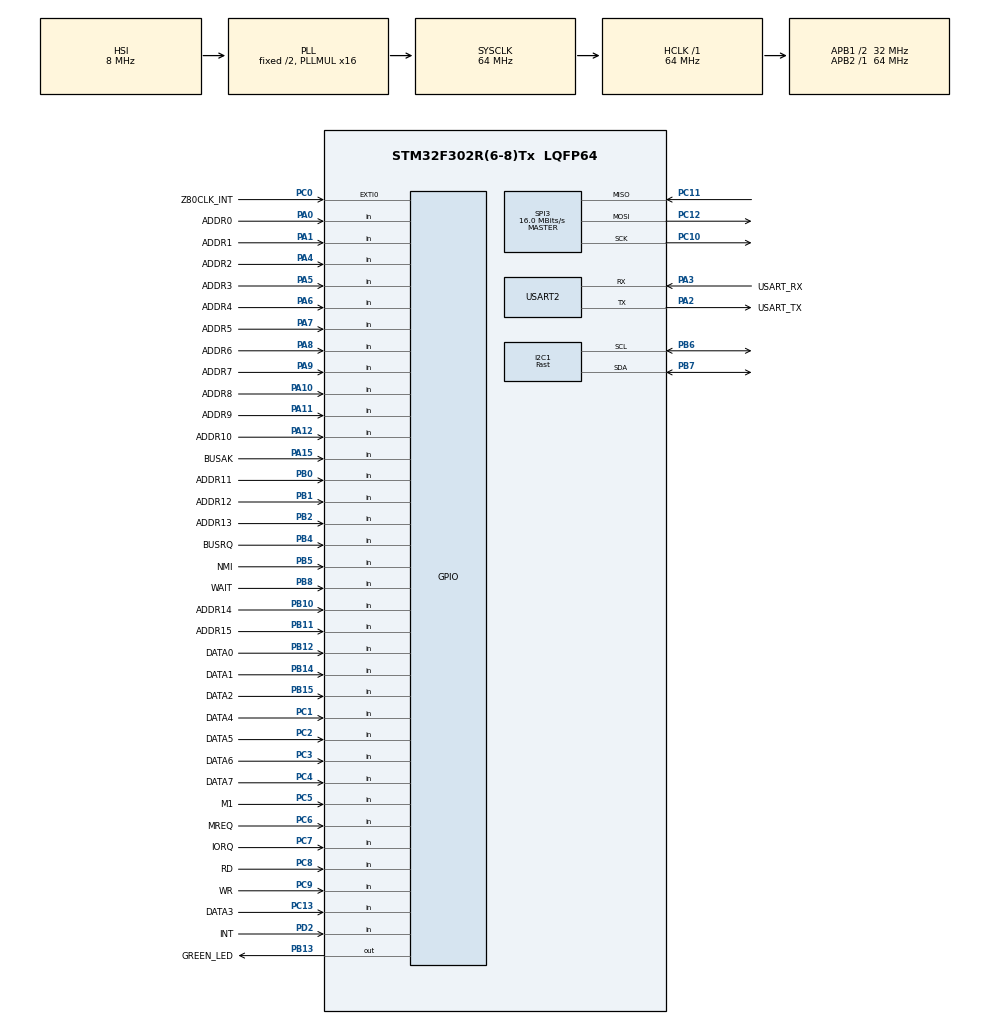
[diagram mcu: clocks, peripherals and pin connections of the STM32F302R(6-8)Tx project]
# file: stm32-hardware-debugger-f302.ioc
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Dma.I2C1_RX.0.Direction=DMA_PERIPH_TO_MEMORY
Dma.I2C1_RX.0.Instance=DMA1_Channel7
Dma.I2C1_RX.0.MemDataAlignment=DMA_MDATAALIGN_BYTE
Dma.I2C1_RX.0.MemInc=DMA_MINC_ENABLE
Dma.I2C1_RX.0.Mode=DMA_NORMAL
Dma.I2C1_RX.0.PeriphDataAlignment=DMA_PDATAALIGN_BYTE
Dma.I2C1_RX.0.PeriphInc=DMA_PINC_DISABLE
Dma.I2C1_RX.0.Priority=DMA_PRIORITY_LOW
Dma.I2C1_TX.1.Direction=DMA_MEMORY_TO_PERIPH
Dma.I2C1_TX.1.Instance=DMA1_Channel6
Dma.I2C1_TX.1.MemDataAlignment=DMA_MDATAALIGN_BYTE
Dma.I2C1_TX.1.MemInc=DMA_MINC_ENABLE
Dma.I2C1_TX.1.Mode=DMA_NORMAL
Dma.I2C1_TX.1.PeriphDataAlignment=DMA_PDATAALIGN_BYTE
Dma.I2C1_TX.1.PeriphInc=DMA_PINC_DISABLE
Dma.I2C1_TX.1.Priority=DMA_PRIORITY_MEDIUM
Dma.Request0=I2C1_RX
Dma.Request1=I2C1_TX
I2C1.I2C_Speed_Mode=I2C_Fast
I2C1.Timing=0x0000020B
Mcu.Family=STM32F3
Mcu.Name=STM32F302R(6-8)Tx
Mcu.Package=LQFP64
NVIC.DMA1_Channel6_IRQn=true\:0\:0\:false\:false\:true\:false\:true
NVIC.DMA1_Channel7_IRQn=true\:0\:0\:false\:false\:true\:false\:true
NVIC.EXTI0_IRQn=true\:0\:0\:false\:false\:true\:true\:true
NVIC.PriorityGroup=NVIC_PRIORITYGROUP_0
PA0.GPIO_Label=ADDR0
PA0.Signal=GPIO_Input
PA1.GPIO_Label=ADDR1
PA1.Signal=GPIO_Input
PA10.GPIO_Label=ADDR8
PA10.Signal=GPIO_Input
PA11.GPIO_Label=ADDR9
PA11.Signal=GPIO_Input
PA12.GPIO_Label=ADDR10
PA12.Signal=GPIO_Input
PA13.GPIO_Label=TMS
PA13.Mode=Serial_Wire
PA13.Signal=SYS_JTMS-SWDIO
PA14.GPIO_Label=TCK
PA14.Mode=Serial_Wire
PA14.Signal=SYS_JTCK-SWCLK
PA15.GPIO_Label=BUSAK
PA15.Signal=GPIO_Input
PA2.GPIO_Label=USART_TX
PA2.GPIO_Mode=GPIO_MODE_AF_PP
PA2.GPIO_PuPd=GPIO_NOPULL
PA2.GPIO_Speed=GPIO_SPEED_FREQ_LOW
PA2.Mode=Asynchronous
PA2.Signal=USART2_TX
PA3.GPIO_Label=USART_RX
PA3.GPIO_Mode=GPIO_MODE_AF_PP
PA3.GPIO_PuPd=GPIO_NOPULL
PA3.GPIO_Speed=GPIO_SPEED_FREQ_LOW
PA3.Mode=Asynchronous
PA3.Signal=USART2_RX
PA4.GPIO_Label=ADDR2
PA4.Signal=GPIO_Input
PA5.GPIO_Label=ADDR3
PA5.Signal=GPIO_Input
PA6.GPIO_Label=ADDR4
PA6.Signal=GPIO_Input
PA7.GPIO_Label=ADDR5
PA7.Signal=GPIO_Input
PA8.GPIO_Label=ADDR6
PA8.Signal=GPIO_Input
PA9.GPIO_Label=ADDR7
PA9.Signal=GPIO_Input
PB0.GPIO_Label=ADDR11
PB0.Signal=GPIO_Input
PB1.GPIO_Label=ADDR12
PB1.Signal=GPIO_Input
PB10.GPIO_Label=ADDR14
PB10.Signal=GPIO_Input
PB11.GPIO_Label=ADDR15
PB11.Signal=GPIO_Input
PB12.GPIO_Label=DATA0
PB12.Signal=GPIO_Input
PB13.GPIO_Label=GREEN_LED
PB13.Signal=GPIO_Output
PB14.GPIO_Label=DATA1
PB14.Signal=GPIO_Input
PB15.GPIO_Label=DATA2
PB15.Signal=GPIO_Input
PB2.GPIO_Label=ADDR13
PB2.Signal=GPIO_Input
PB3.GPIO_Label=SWO
PB3.Mode=Trace_Asynchronous_SW
PB3.Signal=SYS_JTDO-TRACESWO
PB4.GPIO_Label=BUSRQ
PB4.Signal=GPIO_Input
PB5.GPIO_Label=NMI
PB5.Signal=GPIO_Input
PB6.Mode=I2C
PB6.Signal=I2C1_SCL
PB7.Mode=I2C
PB7.Signal=I2C1_SDA
PB8.GPIO_Label=WAIT
PB8.Signal=GPIO_Input
PC0.GPIO_Label=Z80CLK_INT
PC0.Signal=GPXTI0
PC1.GPIO_Label=DATA4
PC1.Signal=GPIO_Input
PC10.Mode=Full_Duplex_Master
PC10.Signal=SPI3_SCK
PC11.Mode=Full_Duplex_Master
PC11.Signal=SPI3_MISO
PC12.Mode=Full_Duplex_Master
PC12.Signal=SPI3_MOSI
PC13.GPIO_Label=DATA3
PC13.Signal=GPIO_Input
PC14\ -\ OSC32_IN.Mode=LSE-External-Oscillator
PC14\ -\ OSC32_IN.Signal=RCC_OSC32_IN
PC15\ -\ OSC32_OUT.Mode=LSE-External-Oscillator
PC15\ -\ OSC32_OUT.Signal=RCC_OSC32_OUT
PC2.GPIO_Label=DATA5
PC2.Signal=GPIO_Input
PC3.GPIO_Label=DATA6
PC3.Signal=GPIO_Input
PC4.GPIO_Label=DATA7
PC4.Signal=GPIO_Input
PC5.GPIO_Label=M1
PC5.Signal=GPIO_Input
PC6.GPIO_Label=MREQ
PC6.Signal=GPIO_Input
PC7.GPIO_Label=IORQ
PC7.Signal=GPIO_Input
PC8.GPIO_Label=RD
PC8.Signal=GPIO_Input
PC9.GPIO_Label=WR
PC9.Signal=GPIO_Input
PD2.GPIO_Label=INT
PD2.Signal=GPIO_Input
PF0-OSC_IN.Mode=HSE-External-Clock-Source
PF0-OSC_IN.Signal=RCC_OSC_IN
PF1-OSC_OUT.Signal=RCC_OSC_OUT
ProjectManager.HeapSize=0x200
ProjectManager.StackSize=0x400
ProjectManager.TargetToolchain=SW4STM32
RCC.AHBFreq_Value=64000000
RCC.APB1CLKDivider=RCC_HCLK_DIV2
RCC.APB1Freq_Value=32000000
RCC.APB1TimFreq_Value=64000000
RCC.APB2Freq_Value=64000000
RCC.APB2TimFreq_Value=64000000
RCC.CortexFreq_Value=64000000
RCC.HCLKFreq_Value=64000000
RCC.HSE_VALUE=8000000
RCC.HSI_VALUE=8000000
RCC.PLLM=8
RCC.PLLMUL=RCC_PLL_MUL16
RCC.PLLN=336
RCC.PLLP=RCC_PLLP_DIV4
RCC.PLLQ=7
RCC.RCC_PLLsource_Clock_Source_FROM_HSE=RCC_HSE_PREDIV_DIV2
RCC.SYSCLKFreq_VALUE=64000000
RCC.SYSCLKSourceVirtual=RCC_SYSCLKSOURCE_PLLCLK
RCC.USBFreq_Value=64000000
SPI3.CalculateBaudRate=16.0 MBits/s
SPI3.Direction=SPI_DIRECTION_2LINES
SPI3.Mode=SPI_MODE_MASTER
SPI3.VirtualType=VM_MASTER
USART2.VirtualMode-Asynchronous=VM_ASYNC
board=NUCLEO-F302R8

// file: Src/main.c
/* USER CODE BEGIN Header */
/**
  ******************************************************************************
  * @file           : main.c
  * @brief          : Main program body
  ******************************************************************************
  * @attention
  *
  * <h2><center>&copy; Copyright (c) 2020 STMicroelectronics.
  * All rights reserved.</center></h2>
  *
  * This software component is licensed by ST under BSD 3-Clause license,
  * the "License"; You may not use this file except in compliance with the
  * License. You may obtain a copy of the License at:
  *                        opensource.org/licenses/BSD-3-Clause
  *
  ******************************************************************************
  */
/* USER CODE END Header */

#include "main.h"

/* USER CODE BEGIN Includes */
#include "my_main.h"
/* USER CODE END Includes */

I2C_HandleTypeDef hi2c1;
DMA_HandleTypeDef hdma_i2c1_rx;
DMA_HandleTypeDef hdma_i2c1_tx;

SPI_HandleTypeDef hspi3;

UART_HandleTypeDef huart2;

void SystemClock_Config(void);
static void MX_GPIO_Init(void);
static void MX_DMA_Init(void);
static void MX_I2C1_Init(void);
static void MX_SPI3_Init(void);
static void MX_USART2_UART_Init(void);

int main(void)
{

  /* MCU Configuration--------------------------------------------------------*/

  /* Reset of all peripherals, Initializes the Flash interface and the Systick. */
  HAL_Init();

  /* Configure the system clock */
  SystemClock_Config();

  /* Initialize all configured peripherals */
  MX_GPIO_Init();
  MX_DMA_Init();
  MX_I2C1_Init();
  MX_SPI3_Init();
  MX_USART2_UART_Init();
  /* USER CODE BEGIN 2 */
  initApp();
  /* USER CODE END 2 */

  /* Infinite loop */
  while (1)
  {

  }
}

void SystemClock_Config(void)
{
  RCC_OscInitTypeDef RCC_OscInitStruct = {0};
  RCC_ClkInitTypeDef RCC_ClkInitStruct = {0};
  RCC_PeriphCLKInitTypeDef PeriphClkInit = {0};

  /** Initializes the CPU, AHB and APB busses clocks
  */
  RCC_OscInitStruct.OscillatorType = RCC_OSCILLATORTYPE_HSI;
  RCC_OscInitStruct.HSIState = RCC_HSI_ON;
  RCC_OscInitStruct.HSICalibrationValue = RCC_HSICALIBRATION_DEFAULT;
  RCC_OscInitStruct.PLL.PLLState = RCC_PLL_ON;
  RCC_OscInitStruct.PLL.PLLSource = RCC_PLLSOURCE_HSI;
  RCC_OscInitStruct.PLL.PLLMUL = RCC_PLL_MUL16;
  if (HAL_RCC_OscConfig(&RCC_OscInitStruct) != HAL_OK)
  {
    Error_Handler();
  }
  /** Initializes the CPU, AHB and APB busses clocks
  */
  RCC_ClkInitStruct.ClockType = RCC_CLOCKTYPE_HCLK|RCC_CLOCKTYPE_SYSCLK
                              |RCC_CLOCKTYPE_PCLK1|RCC_CLOCKTYPE_PCLK2;
  RCC_ClkInitStruct.SYSCLKSource = RCC_SYSCLKSOURCE_PLLCLK;
  RCC_ClkInitStruct.AHBCLKDivider = RCC_SYSCLK_DIV1;
  RCC_ClkInitStruct.APB1CLKDivider = RCC_HCLK_DIV2;
  RCC_ClkInitStruct.APB2CLKDivider = RCC_HCLK_DIV1;

  if (HAL_RCC_ClockConfig(&RCC_ClkInitStruct, FLASH_LATENCY_2) != HAL_OK)
  {
    Error_Handler();
  }
  PeriphClkInit.PeriphClockSelection = RCC_PERIPHCLK_I2C1;
  PeriphClkInit.I2c1ClockSelection = RCC_I2C1CLKSOURCE_HSI;
  if (HAL_RCCEx_PeriphCLKConfig(&PeriphClkInit) != HAL_OK)
  {
    Error_Handler();
  }
}

static void MX_I2C1_Init(void)
{

  hi2c1.Instance = I2C1;
  hi2c1.Init.Timing = 0x0000020B;
  hi2c1.Init.OwnAddress1 = 0;
  hi2c1.Init.AddressingMode = I2C_ADDRESSINGMODE_7BIT;
  hi2c1.Init.DualAddressMode = I2C_DUALADDRESS_DISABLE;
  hi2c1.Init.OwnAddress2 = 0;
  hi2c1.Init.OwnAddress2Masks = I2C_OA2_NOMASK;
  hi2c1.Init.GeneralCallMode = I2C_GENERALCALL_DISABLE;
  hi2c1.Init.NoStretchMode = I2C_NOSTRETCH_DISABLE;
  if (HAL_I2C_Init(&hi2c1) != HAL_OK)
  {
    Error_Handler();
  }
  /** Configure Analogue filter
  */
  if (HAL_I2CEx_ConfigAnalogFilter(&hi2c1, I2C_ANALOGFILTER_ENABLE) != HAL_OK)
  {
    Error_Handler();
  }
  /** Configure Digital filter
  */
  if (HAL_I2CEx_ConfigDigitalFilter(&hi2c1, 0) != HAL_OK)
  {
    Error_Handler();
  }

}

static void MX_SPI3_Init(void)
{

  /* SPI3 parameter configuration*/
  hspi3.Instance = SPI3;
  hspi3.Init.Mode = SPI_MODE_MASTER;
  hspi3.Init.Direction = SPI_DIRECTION_2LINES;
  hspi3.Init.DataSize = SPI_DATASIZE_4BIT;
  hspi3.Init.CLKPolarity = SPI_POLARITY_LOW;
  hspi3.Init.CLKPhase = SPI_PHASE_1EDGE;
  hspi3.Init.NSS = SPI_NSS_SOFT;
  hspi3.Init.BaudRatePrescaler = SPI_BAUDRATEPRESCALER_2;
  hspi3.Init.FirstBit = SPI_FIRSTBIT_MSB;
  hspi3.Init.TIMode = SPI_TIMODE_DISABLE;
  hspi3.Init.CRCCalculation = SPI_CRCCALCULATION_DISABLE;
  hspi3.Init.CRCPolynomial = 7;
  hspi3.Init.CRCLength = SPI_CRC_LENGTH_DATASIZE;
  hspi3.Init.NSSPMode = SPI_NSS_PULSE_ENABLE;
  if (HAL_SPI_Init(&hspi3) != HAL_OK)
  {
    Error_Handler();
  }

}

static void MX_USART2_UART_Init(void)
{

  huart2.Instance = USART2;
  huart2.Init.BaudRate = 38400;
  huart2.Init.WordLength = UART_WORDLENGTH_8B;
  huart2.Init.StopBits = UART_STOPBITS_1;
  huart2.Init.Parity = UART_PARITY_NONE;
  huart2.Init.Mode = UART_MODE_TX_RX;
  huart2.Init.HwFlowCtl = UART_HWCONTROL_NONE;
  huart2.Init.OverSampling = UART_OVERSAMPLING_16;
  huart2.Init.OneBitSampling = UART_ONE_BIT_SAMPLE_DISABLE;
  huart2.AdvancedInit.AdvFeatureInit = UART_ADVFEATURE_NO_INIT;
  if (HAL_UART_Init(&huart2) != HAL_OK)
  {
    Error_Handler();
  }

}

static void MX_DMA_Init(void)
{

  /* DMA controller clock enable */
  __HAL_RCC_DMA1_CLK_ENABLE();

  /* DMA interrupt init */
  /* DMA1_Channel6_IRQn interrupt configuration */
  HAL_NVIC_SetPriority(DMA1_Channel6_IRQn, 0, 0);
  HAL_NVIC_EnableIRQ(DMA1_Channel6_IRQn);
  /* DMA1_Channel7_IRQn interrupt configuration */
  HAL_NVIC_SetPriority(DMA1_Channel7_IRQn, 0, 0);
  HAL_NVIC_EnableIRQ(DMA1_Channel7_IRQn);

}

static void MX_GPIO_Init(void)
{
  GPIO_InitTypeDef GPIO_InitStruct = {0};

  /* GPIO Ports Clock Enable */
  __HAL_RCC_GPIOC_CLK_ENABLE();
  __HAL_RCC_GPIOF_CLK_ENABLE();
  __HAL_RCC_GPIOA_CLK_ENABLE();
  __HAL_RCC_GPIOB_CLK_ENABLE();
  __HAL_RCC_GPIOD_CLK_ENABLE();

  /*Configure GPIO pin Output Level */
  HAL_GPIO_WritePin(GREEN_LED_GPIO_Port, GREEN_LED_Pin, GPIO_PIN_RESET);

  /*Configure GPIO pins : DATA3_Pin DATA4_Pin DATA5_Pin DATA6_Pin
                           DATA7_Pin M1_Pin MREQ_Pin IORQ_Pin
                           RD_Pin WR_Pin */
  GPIO_InitStruct.Pin = DATA3_Pin|DATA4_Pin|DATA5_Pin|DATA6_Pin
                          |DATA7_Pin|M1_Pin|MREQ_Pin|IORQ_Pin
                          |RD_Pin|WR_Pin;
  GPIO_InitStruct.Mode = GPIO_MODE_INPUT;
  GPIO_InitStruct.Pull = GPIO_NOPULL;
  HAL_GPIO_Init(GPIOC, &GPIO_InitStruct);

  /*Configure GPIO pin : Z80CLK_INT_Pin */
  GPIO_InitStruct.Pin = Z80CLK_INT_Pin;
  GPIO_InitStruct.Mode = GPIO_MODE_IT_RISING;
  GPIO_InitStruct.Pull = GPIO_NOPULL;
  HAL_GPIO_Init(Z80CLK_INT_GPIO_Port, &GPIO_InitStruct);

  /*Configure GPIO pins : ADDR0_Pin ADDR1_Pin ADDR2_Pin ADDR3_Pin
                           ADDR4_Pin ADDR5_Pin ADDR6_Pin ADDR7_Pin
                           ADDR8_Pin ADDR9_Pin ADDR10_Pin BUSAK_Pin */
  GPIO_InitStruct.Pin = ADDR0_Pin|ADDR1_Pin|ADDR2_Pin|ADDR3_Pin
                          |ADDR4_Pin|ADDR5_Pin|ADDR6_Pin|ADDR7_Pin
                          |ADDR8_Pin|ADDR9_Pin|ADDR10_Pin|BUSAK_Pin;
  GPIO_InitStruct.Mode = GPIO_MODE_INPUT;
  GPIO_InitStruct.Pull = GPIO_NOPULL;
  HAL_GPIO_Init(GPIOA, &GPIO_InitStruct);

  /*Configure GPIO pins : ADDR11_Pin ADDR12_Pin ADDR13_Pin ADDR14_Pin
                           ADDR15_Pin DATA0_Pin DATA1_Pin DATA2_Pin
                           BUSRQ_Pin NMI_Pin WAIT_Pin */
  GPIO_InitStruct.Pin = ADDR11_Pin|ADDR12_Pin|ADDR13_Pin|ADDR14_Pin
                          |ADDR15_Pin|DATA0_Pin|DATA1_Pin|DATA2_Pin
                          |BUSRQ_Pin|NMI_Pin|WAIT_Pin;
  GPIO_InitStruct.Mode = GPIO_MODE_INPUT;
  GPIO_InitStruct.Pull = GPIO_NOPULL;
  HAL_GPIO_Init(GPIOB, &GPIO_InitStruct);

  /*Configure GPIO pin : GREEN_LED_Pin */
  GPIO_InitStruct.Pin = GREEN_LED_Pin;
  GPIO_InitStruct.Mode = GPIO_MODE_OUTPUT_PP;
  GPIO_InitStruct.Pull = GPIO_NOPULL;
  GPIO_InitStruct.Speed = GPIO_SPEED_FREQ_LOW;
  HAL_GPIO_Init(GREEN_LED_GPIO_Port, &GPIO_InitStruct);

  /*Configure GPIO pin : INT_Pin */
  GPIO_InitStruct.Pin = INT_Pin;
  GPIO_InitStruct.Mode = GPIO_MODE_INPUT;
  GPIO_InitStruct.Pull = GPIO_NOPULL;
  HAL_GPIO_Init(INT_GPIO_Port, &GPIO_InitStruct);

  /* EXTI interrupt init*/
  HAL_NVIC_SetPriority(EXTI0_IRQn, 0, 0);
  HAL_NVIC_EnableIRQ(EXTI0_IRQn);

}

void Error_Handler(void)
{
}

/************************ (C) COPYRIGHT STMicroelectronics *****END OF FILE****/
